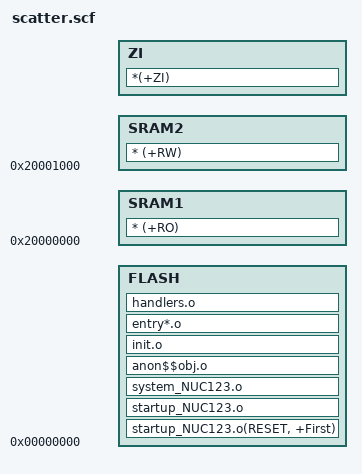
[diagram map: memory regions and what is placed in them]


FLASH 0x00000000
{
    FLASH +0
    {
         startup_NUC123.o(RESET, +First)
         startup_NUC123.o
         system_NUC123.o
         anon$$obj.o
         init.o
         entry*.o
         handlers.o
    }

    SRAM1 0x20000000
    {  
        * (+RO)
    }

    SRAM2 0x20001000
    {
        * (+RW)
    
    }

    ZI +0
    {
        *(+ZI)
    }

}

